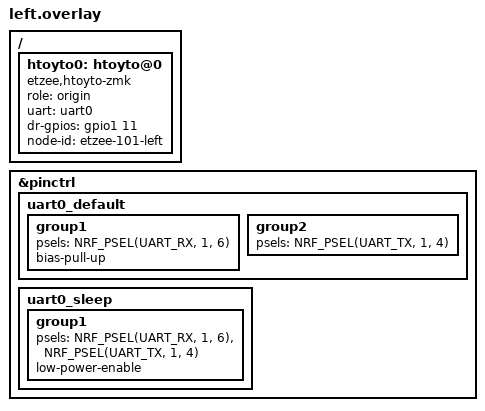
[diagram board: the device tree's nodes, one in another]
/ {
    htoyto0: htoyto@0 {
        compatible = "etzee,htoyto-zmk";
        status = "okay";
        role = "origin";
        uart = <&uart0>;
        dr-gpios = <&gpio1 11 (GPIO_ACTIVE_HIGH | GPIO_PULL_DOWN)>;
        node-id = "etzee-101-left";
    };
};

&pinctrl {
    uart0_default: uart0_default {
        group1 {
            psels = <NRF_PSEL(UART_RX, 1, 6)>; // RX = P1.06
            bias-pull-up;
        };
        group2 {
            psels = <NRF_PSEL(UART_TX, 1, 4)>; // TX = P1.04
        };
    };

    uart0_sleep: uart0_sleep {
        group1 {
            psels = <NRF_PSEL(UART_RX, 1, 6)>,
                    <NRF_PSEL(UART_TX, 1, 4)>;
            low-power-enable;
        };
    };
};
